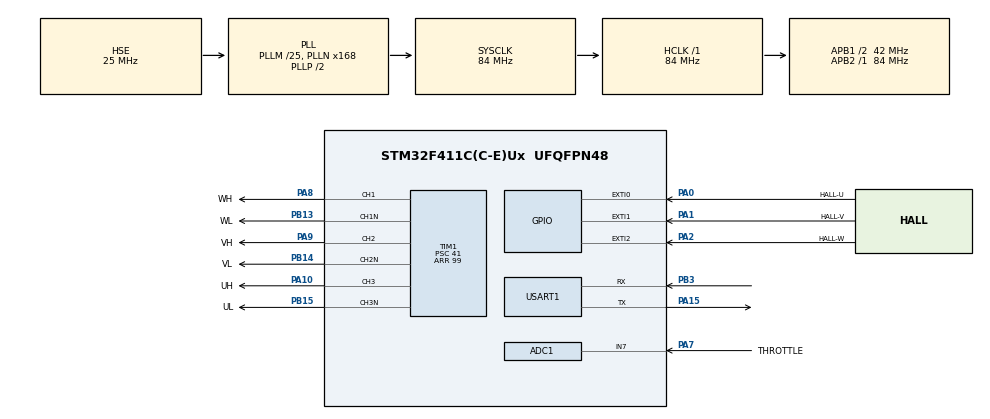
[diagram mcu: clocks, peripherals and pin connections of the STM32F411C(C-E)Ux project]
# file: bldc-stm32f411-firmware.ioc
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ADC1.Channel-0\#ChannelRegularConversion=ADC_CHANNEL_7
ADC1.ContinuousConvMode=ENABLE
ADC1.DMAContinuousRequests=ENABLE
ADC1.NbrOfConversion=1
ADC1.NbrOfConversionFlag=1
ADC1.Rank-0\#ChannelRegularConversion=1
ADC1.SamplingTime-0\#ChannelRegularConversion=ADC_SAMPLETIME_3CYCLES
ADC1.master=1
Dma.ADC1.0.Direction=DMA_PERIPH_TO_MEMORY
Dma.ADC1.0.FIFOMode=DMA_FIFOMODE_DISABLE
Dma.ADC1.0.Instance=DMA2_Stream0
Dma.ADC1.0.MemDataAlignment=DMA_MDATAALIGN_HALFWORD
Dma.ADC1.0.MemInc=DMA_MINC_ENABLE
Dma.ADC1.0.Mode=DMA_CIRCULAR
Dma.ADC1.0.PeriphDataAlignment=DMA_PDATAALIGN_HALFWORD
Dma.ADC1.0.PeriphInc=DMA_PINC_DISABLE
Dma.ADC1.0.Priority=DMA_PRIORITY_HIGH
Dma.Request0=ADC1
Mcu.Family=STM32F4
Mcu.Name=STM32F411C(C-E)Ux
Mcu.Package=UFQFPN48
NVIC.DMA2_Stream0_IRQn=true\:0\:0\:false\:false\:true\:false\:true\:true
NVIC.EXTI0_IRQn=true\:0\:0\:false\:true\:true\:1\:true\:true\:true
NVIC.EXTI1_IRQn=true\:0\:0\:false\:true\:true\:2\:true\:true\:true
NVIC.EXTI2_IRQn=true\:0\:0\:false\:true\:true\:3\:true\:true\:true
NVIC.PriorityGroup=NVIC_PRIORITYGROUP_4
NVIC.TIM1_CC_IRQn=true\:0\:0\:false\:false\:true\:true\:true\:true
PA0-WKUP.GPIO_Label=HALL-U
PA0-WKUP.GPIO_ModeDefaultEXTI=GPIO_MODE_IT_RISING_FALLING
PA0-WKUP.Signal=GPXTI0
PA1.GPIO_Label=HALL-V
PA1.GPIO_ModeDefaultEXTI=GPIO_MODE_IT_RISING_FALLING
PA1.Signal=GPXTI1
PA10.GPIO_Label=UH
PA10.GPIO_Speed=GPIO_SPEED_FREQ_VERY_HIGH
PA10.Signal=S_TIM1_CH3
PA13.Mode=Serial_Wire
PA13.Signal=SYS_JTMS-SWDIO
PA14.Mode=Serial_Wire
PA14.Signal=SYS_JTCK-SWCLK
PA15.Mode=Asynchronous
PA15.Signal=USART1_TX
PA2.GPIO_Label=HALL-W
PA2.GPIO_ModeDefaultEXTI=GPIO_MODE_IT_RISING_FALLING
PA2.Signal=GPXTI2
PA7.GPIO_Label=THROTTLE
PA7.Signal=ADCx_IN7
PA8.GPIO_Label=WH
PA8.GPIO_Speed=GPIO_SPEED_FREQ_VERY_HIGH
PA8.Signal=S_TIM1_CH1
PA9.GPIO_Label=VH
PA9.GPIO_Speed=GPIO_SPEED_FREQ_VERY_HIGH
PA9.Signal=S_TIM1_CH2
PB13.GPIO_Label=WL
PB13.GPIO_Speed=GPIO_SPEED_FREQ_VERY_HIGH
PB13.Mode=PWM Generation1 CH1 CH1N
PB13.Signal=TIM1_CH1N
PB14.GPIO_Label=VL
PB14.GPIO_Speed=GPIO_SPEED_FREQ_VERY_HIGH
PB14.Mode=PWM Generation2 CH2 CH2N
PB14.Signal=TIM1_CH2N
PB15.GPIO_Label=UL
PB15.GPIO_Speed=GPIO_SPEED_FREQ_VERY_HIGH
PB15.Mode=PWM Generation3 CH3 CH3N
PB15.Signal=TIM1_CH3N
PB3.Mode=Asynchronous
PB3.Signal=USART1_RX
PH0\ -\ OSC_IN.Mode=HSE-External-Oscillator
PH0\ -\ OSC_IN.Signal=RCC_OSC_IN
PH1\ -\ OSC_OUT.Mode=HSE-External-Oscillator
PH1\ -\ OSC_OUT.Signal=RCC_OSC_OUT
ProjectManager.HeapSize=0x200
ProjectManager.StackSize=0x400
ProjectManager.TargetToolchain=STM32CubeIDE
RCC.48MHZClocksFreq_Value=42000000
RCC.AHBFreq_Value=84000000
RCC.APB1CLKDivider=RCC_HCLK_DIV2
RCC.APB1Freq_Value=42000000
RCC.APB1TimFreq_Value=84000000
RCC.APB2Freq_Value=84000000
RCC.APB2TimFreq_Value=84000000
RCC.CortexFreq_Value=84000000
RCC.HCLKFreq_Value=84000000
RCC.HSE_VALUE=25000000
RCC.HSI_VALUE=16000000
RCC.LSE_VALUE=32768
RCC.PLLM=25
RCC.PLLN=168
RCC.PLLSourceVirtual=RCC_PLLSOURCE_HSE
RCC.SYSCLKFreq_VALUE=84000000
RCC.SYSCLKSource=RCC_SYSCLKSOURCE_PLLCLK
RCC.VCOOutputFreq_Value=168000000
SH.ADCx_IN7.0=ADC1_IN7,IN7
SH.S_TIM1_CH1.0=TIM1_CH1,PWM Generation1 CH1 CH1N
SH.S_TIM1_CH2.0=TIM1_CH2,PWM Generation2 CH2 CH2N
SH.S_TIM1_CH3.0=TIM1_CH3,PWM Generation3 CH3 CH3N
TIM1.Channel-PWM\ Generation1\ CH1\ CH1N=TIM_CHANNEL_1
TIM1.Channel-PWM\ Generation2\ CH2\ CH2N=TIM_CHANNEL_2
TIM1.Channel-PWM\ Generation3\ CH3\ CH3N=TIM_CHANNEL_3
TIM1.Period=99
TIM1.Prescaler=41
USART1.VirtualMode=VM_ASYNC
VP_TIM1_VS_ClockSourceINT.Mode=Internal
board=custom

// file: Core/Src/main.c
/* USER CODE BEGIN Header */
/**
  ******************************************************************************
  * @file           : main.c
  * @brief          : Main program body
  ******************************************************************************
  * @attention
  *
  * Copyright (c) 2024 STMicroelectronics.
  * All rights reserved.
  *
  * This software is licensed under terms that can be found in the LICENSE file
  * in the root directory of this software component.
  * If no LICENSE file comes with this software, it is provided AS-IS.
  *
  ******************************************************************************
  */
/* USER CODE END Header */
#include "main.h"

/* USER CODE BEGIN Includes */

#include <stdio.h>
#include <string.h>

/* USER CODE END Includes */

ADC_HandleTypeDef hadc1;
DMA_HandleTypeDef hdma_adc1;

TIM_HandleTypeDef htim1;

UART_HandleTypeDef huart1;

/* USER CODE BEGIN PV */

uint8_t HALL_STATE = 0;
char MSG_HALL_STATE[10];

uint32_t ADC_THROTTLE_VALUE = 0;
float THROTTLE_PERCENTAGE = 0.0;

/* USER CODE END PV */

void SystemClock_Config(void);
static void MX_GPIO_Init(void);
static void MX_DMA_Init(void);
static void MX_USART1_UART_Init(void);
static void MX_ADC1_Init(void);
static void MX_TIM1_Init(void);
static void MX_NVIC_Init(void);
/* USER CODE BEGIN PFP */

void SET_COMMUTATION(uint8_t HALL_STATE);

/* USER CODE END PFP */

int main(void)
{

  /* MCU Configuration--------------------------------------------------------*/

  /* Reset of all peripherals, Initializes the Flash interface and the Systick. */
  HAL_Init();

  /* USER CODE BEGIN Init */

  HAL_ADC_Start_DMA(&hadc1, &ADC_THROTTLE_VALUE, 1);

  HAL_TIM_PWM_Start(&htim1, TIM_CHANNEL_1);
  HAL_TIMEx_PWMN_Start(&htim1, TIM_CHANNEL_1);
  HAL_TIM_PWM_Start(&htim1, TIM_CHANNEL_2);
  HAL_TIMEx_PWMN_Start(&htim1, TIM_CHANNEL_2);
  HAL_TIM_PWM_Start(&htim1, TIM_CHANNEL_3);
  HAL_TIMEx_PWMN_Start(&htim1, TIM_CHANNEL_3);

  /* USER CODE END Init */

  /* Configure the system clock */
  SystemClock_Config();

  /* Initialize all configured peripherals */
  MX_GPIO_Init();
  MX_DMA_Init();
  MX_USART1_UART_Init();
  MX_ADC1_Init();
  MX_TIM1_Init();

  /* Initialize interrupts */
  MX_NVIC_Init();

  /* Infinite loop */
  while (1)
  {

  }
}

void HAL_GPIO_EXTI_Callback(uint16_t GPIO_Pin){
	if (GPIO_Pin == HALL_U_Pin || GPIO_Pin == HALL_V_Pin || GPIO_Pin == HALL_W_Pin) {
		HALL_STATE = 	(HAL_GPIO_ReadPin(HALL_U_GPIO_Port, HALL_U_Pin) << 2)|
						(HAL_GPIO_ReadPin(HALL_V_GPIO_Port, HALL_V_Pin) << 1)|
						 HAL_GPIO_ReadPin(HALL_W_GPIO_Port, HALL_W_Pin);

		SET_COMMUTATION(HALL_STATE);

		sprintf(MSG_HALL_STATE, "HALL: %d\r\n", HALL_STATE);
		HAL_UART_Transmit(&huart1, (uint8_t*)MSG_HALL_STATE, strlen(MSG_HALL_STATE), HAL_MAX_DELAY);
	}
}

void HAL_ADC_ConvCpltCallback(ADC_HandleTypeDef *hadc){
	if (hadc -> Instance == ADC1) {
		THROTTLE_PERCENTAGE = (ADC_THROTTLE_VALUE * 100) / 4095;
	}
}

void SET_COMMUTATION(uint8_t HALL_STATE){
	switch (HALL_STATE) {
		case 0b101: // UH+ WL-
			__HAL_TIM_SET_COMPARE(&htim1, TIM_CHANNEL_1, THROTTLE_PERCENTAGE);
			__HAL_TIM_SET_COMPARE(&htim1, TIM_CHANNEL_3, 0);
			break;
		case 0b001: // VH+ UL-
			__HAL_TIM_SET_COMPARE(&htim1, TIM_CHANNEL_2, THROTTLE_PERCENTAGE);
			__HAL_TIM_SET_COMPARE(&htim1, TIM_CHANNEL_1, 0);
			break;
		case 0b011: // WH+ VL-
			__HAL_TIM_SET_COMPARE(&htim1, TIM_CHANNEL_3, THROTTLE_PERCENTAGE);
			__HAL_TIM_SET_COMPARE(&htim1, TIM_CHANNEL_2, 0);
			break;
		case 0b010: // UH+ VL-
			__HAL_TIM_SET_COMPARE(&htim1, TIM_CHANNEL_1, THROTTLE_PERCENTAGE);
			__HAL_TIM_SET_COMPARE(&htim1, TIM_CHANNEL_2, 0);
			break;
		case 0b110: // VH+ WL-
			__HAL_TIM_SET_COMPARE(&htim1, TIM_CHANNEL_2, THROTTLE_PERCENTAGE);
			__HAL_TIM_SET_COMPARE(&htim1, TIM_CHANNEL_3, 0);
			break;
		case 0b100: // WH+ UL-
			__HAL_TIM_SET_COMPARE(&htim1, TIM_CHANNEL_3, THROTTLE_PERCENTAGE);
			__HAL_TIM_SET_COMPARE(&htim1, TIM_CHANNEL_1, 0);
			break;
		default:
			// Disable all PWMs
			__HAL_TIM_SET_COMPARE(&htim1, TIM_CHANNEL_1, 0);
			__HAL_TIM_SET_COMPARE(&htim1, TIM_CHANNEL_2, 0);
			__HAL_TIM_SET_COMPARE(&htim1, TIM_CHANNEL_3, 0);
			break;
	}
}

void SystemClock_Config(void)
{
  RCC_OscInitTypeDef RCC_OscInitStruct = {0};
  RCC_ClkInitTypeDef RCC_ClkInitStruct = {0};

  /** Configure the main internal regulator output voltage
  */
  __HAL_RCC_PWR_CLK_ENABLE();
  __HAL_PWR_VOLTAGESCALING_CONFIG(PWR_REGULATOR_VOLTAGE_SCALE1);

  /** Initializes the RCC Oscillators according to the specified parameters
  * in the RCC_OscInitTypeDef structure.
  */
  RCC_OscInitStruct.OscillatorType = RCC_OSCILLATORTYPE_HSE;
  RCC_OscInitStruct.HSEState = RCC_HSE_ON;
  RCC_OscInitStruct.PLL.PLLState = RCC_PLL_ON;
  RCC_OscInitStruct.PLL.PLLSource = RCC_PLLSOURCE_HSE;
  RCC_OscInitStruct.PLL.PLLM = 25;
  RCC_OscInitStruct.PLL.PLLN = 168;
  RCC_OscInitStruct.PLL.PLLP = RCC_PLLP_DIV2;
  RCC_OscInitStruct.PLL.PLLQ = 4;
  if (HAL_RCC_OscConfig(&RCC_OscInitStruct) != HAL_OK)
  {
    Error_Handler();
  }

  /** Initializes the CPU, AHB and APB buses clocks
  */
  RCC_ClkInitStruct.ClockType = RCC_CLOCKTYPE_HCLK|RCC_CLOCKTYPE_SYSCLK
                              |RCC_CLOCKTYPE_PCLK1|RCC_CLOCKTYPE_PCLK2;
  RCC_ClkInitStruct.SYSCLKSource = RCC_SYSCLKSOURCE_PLLCLK;
  RCC_ClkInitStruct.AHBCLKDivider = RCC_SYSCLK_DIV1;
  RCC_ClkInitStruct.APB1CLKDivider = RCC_HCLK_DIV2;
  RCC_ClkInitStruct.APB2CLKDivider = RCC_HCLK_DIV1;

  if (HAL_RCC_ClockConfig(&RCC_ClkInitStruct, FLASH_LATENCY_2) != HAL_OK)
  {
    Error_Handler();
  }
}

/**
  * @brief NVIC Configuration.
  * @retval None
  */
static void MX_NVIC_Init(void)
{
  /* EXTI0_IRQn interrupt configuration */
  HAL_NVIC_SetPriority(EXTI0_IRQn, 0, 0);
  HAL_NVIC_EnableIRQ(EXTI0_IRQn);
  /* EXTI1_IRQn interrupt configuration */
  HAL_NVIC_SetPriority(EXTI1_IRQn, 0, 0);
  HAL_NVIC_EnableIRQ(EXTI1_IRQn);
  /* EXTI2_IRQn interrupt configuration */
  HAL_NVIC_SetPriority(EXTI2_IRQn, 0, 0);
  HAL_NVIC_EnableIRQ(EXTI2_IRQn);
}

static void MX_ADC1_Init(void)
{

  ADC_ChannelConfTypeDef sConfig = {0};

  /** Configure the global features of the ADC (Clock, Resolution, Data Alignment and number of conversion)
  */
  hadc1.Instance = ADC1;
  hadc1.Init.ClockPrescaler = ADC_CLOCK_SYNC_PCLK_DIV4;
  hadc1.Init.Resolution = ADC_RESOLUTION_12B;
  hadc1.Init.ScanConvMode = DISABLE;
  hadc1.Init.ContinuousConvMode = ENABLE;
  hadc1.Init.DiscontinuousConvMode = DISABLE;
  hadc1.Init.ExternalTrigConvEdge = ADC_EXTERNALTRIGCONVEDGE_NONE;
  hadc1.Init.ExternalTrigConv = ADC_SOFTWARE_START;
  hadc1.Init.DataAlign = ADC_DATAALIGN_RIGHT;
  hadc1.Init.NbrOfConversion = 1;
  hadc1.Init.DMAContinuousRequests = ENABLE;
  hadc1.Init.EOCSelection = ADC_EOC_SINGLE_CONV;
  if (HAL_ADC_Init(&hadc1) != HAL_OK)
  {
    Error_Handler();
  }

  /** Configure for the selected ADC regular channel its corresponding rank in the sequencer and its sample time.
  */
  sConfig.Channel = ADC_CHANNEL_7;
  sConfig.Rank = 1;
  sConfig.SamplingTime = ADC_SAMPLETIME_3CYCLES;
  if (HAL_ADC_ConfigChannel(&hadc1, &sConfig) != HAL_OK)
  {
    Error_Handler();
  }

}

static void MX_TIM1_Init(void)
{

  TIM_ClockConfigTypeDef sClockSourceConfig = {0};
  TIM_MasterConfigTypeDef sMasterConfig = {0};
  TIM_OC_InitTypeDef sConfigOC = {0};
  TIM_BreakDeadTimeConfigTypeDef sBreakDeadTimeConfig = {0};

  htim1.Instance = TIM1;
  htim1.Init.Prescaler = 41;
  htim1.Init.CounterMode = TIM_COUNTERMODE_UP;
  htim1.Init.Period = 99;
  htim1.Init.ClockDivision = TIM_CLOCKDIVISION_DIV1;
  htim1.Init.RepetitionCounter = 0;
  htim1.Init.AutoReloadPreload = TIM_AUTORELOAD_PRELOAD_DISABLE;
  if (HAL_TIM_Base_Init(&htim1) != HAL_OK)
  {
    Error_Handler();
  }
  sClockSourceConfig.ClockSource = TIM_CLOCKSOURCE_INTERNAL;
  if (HAL_TIM_ConfigClockSource(&htim1, &sClockSourceConfig) != HAL_OK)
  {
    Error_Handler();
  }
  if (HAL_TIM_PWM_Init(&htim1) != HAL_OK)
  {
    Error_Handler();
  }
  sMasterConfig.MasterOutputTrigger = TIM_TRGO_RESET;
  sMasterConfig.MasterSlaveMode = TIM_MASTERSLAVEMODE_DISABLE;
  if (HAL_TIMEx_MasterConfigSynchronization(&htim1, &sMasterConfig) != HAL_OK)
  {
    Error_Handler();
  }
  sConfigOC.OCMode = TIM_OCMODE_PWM1;
  sConfigOC.Pulse = 0;
  sConfigOC.OCPolarity = TIM_OCPOLARITY_HIGH;
  sConfigOC.OCNPolarity = TIM_OCNPOLARITY_HIGH;
  sConfigOC.OCFastMode = TIM_OCFAST_DISABLE;
  sConfigOC.OCIdleState = TIM_OCIDLESTATE_RESET;
  sConfigOC.OCNIdleState = TIM_OCNIDLESTATE_RESET;
  if (HAL_TIM_PWM_ConfigChannel(&htim1, &sConfigOC, TIM_CHANNEL_1) != HAL_OK)
  {
    Error_Handler();
  }
  if (HAL_TIM_PWM_ConfigChannel(&htim1, &sConfigOC, TIM_CHANNEL_2) != HAL_OK)
  {
    Error_Handler();
  }
  if (HAL_TIM_PWM_ConfigChannel(&htim1, &sConfigOC, TIM_CHANNEL_3) != HAL_OK)
  {
    Error_Handler();
  }
  sBreakDeadTimeConfig.OffStateRunMode = TIM_OSSR_DISABLE;
  sBreakDeadTimeConfig.OffStateIDLEMode = TIM_OSSI_DISABLE;
  sBreakDeadTimeConfig.LockLevel = TIM_LOCKLEVEL_OFF;
  sBreakDeadTimeConfig.DeadTime = 0;
  sBreakDeadTimeConfig.BreakState = TIM_BREAK_DISABLE;
  sBreakDeadTimeConfig.BreakPolarity = TIM_BREAKPOLARITY_HIGH;
  sBreakDeadTimeConfig.AutomaticOutput = TIM_AUTOMATICOUTPUT_DISABLE;
  if (HAL_TIMEx_ConfigBreakDeadTime(&htim1, &sBreakDeadTimeConfig) != HAL_OK)
  {
    Error_Handler();
  }
  HAL_TIM_MspPostInit(&htim1);

}

static void MX_USART1_UART_Init(void)
{

  huart1.Instance = USART1;
  huart1.Init.BaudRate = 115200;
  huart1.Init.WordLength = UART_WORDLENGTH_8B;
  huart1.Init.StopBits = UART_STOPBITS_1;
  huart1.Init.Parity = UART_PARITY_NONE;
  huart1.Init.Mode = UART_MODE_TX_RX;
  huart1.Init.HwFlowCtl = UART_HWCONTROL_NONE;
  huart1.Init.OverSampling = UART_OVERSAMPLING_16;
  if (HAL_UART_Init(&huart1) != HAL_OK)
  {
    Error_Handler();
  }

}

static void MX_DMA_Init(void)
{

  /* DMA controller clock enable */
  __HAL_RCC_DMA2_CLK_ENABLE();

  /* DMA interrupt init */
  /* DMA2_Stream0_IRQn interrupt configuration */
  HAL_NVIC_SetPriority(DMA2_Stream0_IRQn, 0, 0);
  HAL_NVIC_EnableIRQ(DMA2_Stream0_IRQn);

}

static void MX_GPIO_Init(void)
{
  GPIO_InitTypeDef GPIO_InitStruct = {0};

  /* GPIO Ports Clock Enable */
  __HAL_RCC_GPIOH_CLK_ENABLE();
  __HAL_RCC_GPIOA_CLK_ENABLE();
  __HAL_RCC_GPIOB_CLK_ENABLE();

  /*Configure GPIO pins : HALL_U_Pin HALL_V_Pin HALL_W_Pin */
  GPIO_InitStruct.Pin = HALL_U_Pin|HALL_V_Pin|HALL_W_Pin;
  GPIO_InitStruct.Mode = GPIO_MODE_IT_RISING_FALLING;
  GPIO_InitStruct.Pull = GPIO_NOPULL;
  HAL_GPIO_Init(GPIOA, &GPIO_InitStruct);

}

void Error_Handler(void)
{
  __disable_irq();
  while (1)
  {
  }
}
